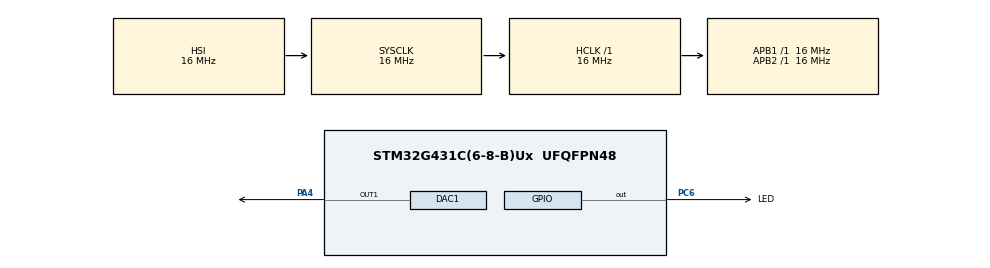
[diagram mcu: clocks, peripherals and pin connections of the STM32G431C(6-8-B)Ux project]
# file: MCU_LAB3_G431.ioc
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Mcu.Family=STM32G4
Mcu.Name=STM32G431C(6-8-B)Ux
Mcu.Package=UFQFPN48
NVIC.PriorityGroup=NVIC_PRIORITYGROUP_4
NVIC.TIM1_BRK_TIM15_IRQn=true\:0\:0\:false\:false\:true\:true\:true\:true
NVIC.TIM1_CC_IRQn=true\:0\:0\:false\:false\:true\:true\:true\:true
NVIC.TIM1_TRG_COM_TIM17_IRQn=true\:0\:0\:false\:false\:true\:true\:true\:true
NVIC.TIM1_UP_TIM16_IRQn=true\:0\:0\:false\:false\:true\:true\:true\:true
PA4.Signal=COMP_DAC11_group
PC6.GPIO_Label=LED
PC6.Signal=GPIO_Output
ProjectManager.HeapSize=0x200
ProjectManager.StackSize=0x400
ProjectManager.TargetToolchain=STM32CubeIDE
RCC.AHBFreq_Value=16000000
RCC.APB1Freq_Value=16000000
RCC.APB1TimFreq_Value=16000000
RCC.APB2Freq_Value=16000000
RCC.APB2TimFreq_Value=16000000
RCC.CortexFreq_Value=16000000
RCC.EXTERNAL_CLOCK_VALUE=12288000
RCC.HCLKFreq_Value=16000000
RCC.HSE_VALUE=8000000
RCC.HSI48_VALUE=48000000
RCC.HSI_VALUE=16000000
RCC.LSE_VALUE=32768
RCC.SYSCLKFreq_VALUE=16000000
RCC.USBFreq_Value=64000000
RCC.VCOOutputFreq_Value=128000000
SH.COMP_DAC11_group.0=DAC1_OUT1,DAC_OUT1
TIM1.PeriodNoDither=10000+1
TIM1.Prescaler=16+1
VP_SYS_VS_DBSignals.Mode=DisableDeadBatterySignals
VP_TIM1_VS_ClockSourceINT.Mode=Internal
board=custom

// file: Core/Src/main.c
/* USER CODE BEGIN Header */
/**
  ******************************************************************************
  * @file           : main.c
  * @brief          : Main program body
  ******************************************************************************
  * @attention
  *
  * Copyright (c) 2024 STMicroelectronics.
  * All rights reserved.
  *
  * This software is licensed under terms that can be found in the LICENSE file
  * in the root directory of this software component.
  * If no LICENSE file comes with this software, it is provided AS-IS.
  *
  ******************************************************************************
  */
/* USER CODE END Header */
#include "main.h"

/* USER CODE BEGIN Includes */
#include <math.h>
#include <stdio.h>
#include <stdbool.h>
#include <string.h>
/* USER CODE END Includes */

DAC_HandleTypeDef hdac1;

TIM_HandleTypeDef htim1;

void SystemClock_Config(void);
static void MX_GPIO_Init(void);
static void MX_DAC1_Init(void);
static void MX_TIM1_Init(void);

/* USER CODE BEGIN 0 */

int num = 0;
uint32_t time = 0;

char rx_buffer[10];
char tx_buffer[50];
bool cmd_executed = false;

float received_numbers[2];
int numbers_received = 0;

uint32_t w = 0;
float omega = 1.0;

uint32_t wave(uint32_t t);

float phi = -3.14 / 2.0;
float ampl = 0.5;

uint32_t wave(uint32_t t) {
	uint32_t ns = 50; // ns = number samples || ns = 10 - bad || ns = 255 - good
	float v_ref = 3.3;
	float freq = 60.0; // in Hz, should be the same as timer clock
	// 1000000/freq . 16 bit, then PSC need incresde to -> another formula we need
	// my method
	TIM1->ARR = (uint32_t) (1000000/freq);
	TIM1->PSC = 16 + 1;

	// stm method
//	TIM1->ARR = (uint32_t) (1000000/(ns*freq));
//	TIM1->PSC = 16 + 1;
//	omega = 2.0 * 3.14 * freq;
	float b = 0.5;
	float res = b + ampl * sinf( (omega * t)/ns + phi);

	return (uint32_t) ((res / v_ref)* 4096);
//	return (uint32_t) (v_ref/2) * ( ampl * sin( (6.28/ns)*t ) + 1 );

//	// 12-битное DAC, максимальное значение - 0xFFF
//	const uint32_t DAC_MaxDigitalValue = 0xFFF;
//
//	// Угол для текущего сэмпла с учётом фазового сдвига
//	float angle = ((2.0f * 3.14159f * t) / ns) + phi;
//
//	// Генерация значения синуса и масштабирование в диапазон от 0 до DAC_MaxDigitalValue
//	float sineValue = (uint32_t) (sinf(angle) + 1.0f);
//
//	// Преобразование в цифровое значение для DAC (с учётом VREF)
//	return (uint32_t) ( 4096 * (sineValue / (3.3/2)) );

}

//void get_sineval ()
//{
//	for (int i=0;i<1000;i++)
//	{
//		sine_val[i] = ((sin(i*2*3.14/100) + 1)*(4096/2));
//
//	}
//}

void HAL_TIM_PeriodElapsedCallback(TIM_HandleTypeDef *htim){
	if (htim == &htim1){
		if(htim->Instance == TIM1){
			time++; // t is discrete
			w = wave(time);
			HAL_DAC_SetValue(&hdac1, DAC_CHANNEL_1, DAC_ALIGN_12B_R, w);

//			uint8_t buff[10];
//			num++;
//			sprintf(buff, "%d", num);

//			HAL_UART_Transmit_IT(&huart2, buff, 10);
			HAL_GPIO_TogglePin(LED_GPIO_Port, LED_Pin);

		}
	}
}

//void HAL_UART_RxCpltCallback(UART_HandleTypeDef *huart) {
////    if (huart->Instance == USART2 {
//
//        float number;
//        if (sscanf(rx_buffer, "%f", &number) == 1) {
//            received_numbers[numbers_received] = number;
//            numbers_received++;
//        }
//
//        if (numbers_received == 2) {
//            snprintf(tx_buffer, sizeof(tx_buffer), "got numbers, plotting a sin\n");
//            HAL_UART_Transmit(&huart2, (uint8_t*)tx_buffer, strlen(tx_buffer), HAL_MAX_DELAY);
//
//            numbers_received = 0;
//        }
//
//        memset(rx_buffer, 0, sizeof(rx_buffer));
//        HAL_UART_Receive_IT(&huart2, (uint8_t*)rx_buffer, sizeof(rx_buffer) - 1);
//}

/* USER CODE END 0 */

int main(void)
{

  /* MCU Configuration--------------------------------------------------------*/

  /* Reset of all peripherals, Initializes the Flash interface and the Systick. */
  HAL_Init();

  /* Configure the system clock */
  SystemClock_Config();

  /* Initialize all configured peripherals */
  MX_GPIO_Init();
  MX_DAC1_Init();
  MX_TIM1_Init();
  /* USER CODE BEGIN 2 */
  HAL_DAC_Start(&hdac1, DAC_CHANNEL_1);
  HAL_TIM_Base_Start_IT(&htim1);
  /* USER CODE END 2 */

  /* Infinite loop */
  while (1)
  {

  }
}

void SystemClock_Config(void)
{
  RCC_OscInitTypeDef RCC_OscInitStruct = {0};
  RCC_ClkInitTypeDef RCC_ClkInitStruct = {0};

  /** Configure the main internal regulator output voltage
  */
  HAL_PWREx_ControlVoltageScaling(PWR_REGULATOR_VOLTAGE_SCALE1);

  /** Initializes the RCC Oscillators according to the specified parameters
  * in the RCC_OscInitTypeDef structure.
  */
  RCC_OscInitStruct.OscillatorType = RCC_OSCILLATORTYPE_HSI;
  RCC_OscInitStruct.HSIState = RCC_HSI_ON;
  RCC_OscInitStruct.HSICalibrationValue = RCC_HSICALIBRATION_DEFAULT;
  RCC_OscInitStruct.PLL.PLLState = RCC_PLL_NONE;
  if (HAL_RCC_OscConfig(&RCC_OscInitStruct) != HAL_OK)
  {
    Error_Handler();
  }

  /** Initializes the CPU, AHB and APB buses clocks
  */
  RCC_ClkInitStruct.ClockType = RCC_CLOCKTYPE_HCLK|RCC_CLOCKTYPE_SYSCLK
                              |RCC_CLOCKTYPE_PCLK1|RCC_CLOCKTYPE_PCLK2;
  RCC_ClkInitStruct.SYSCLKSource = RCC_SYSCLKSOURCE_HSI;
  RCC_ClkInitStruct.AHBCLKDivider = RCC_SYSCLK_DIV1;
  RCC_ClkInitStruct.APB1CLKDivider = RCC_HCLK_DIV1;
  RCC_ClkInitStruct.APB2CLKDivider = RCC_HCLK_DIV1;

  if (HAL_RCC_ClockConfig(&RCC_ClkInitStruct, FLASH_LATENCY_0) != HAL_OK)
  {
    Error_Handler();
  }
}

static void MX_DAC1_Init(void)
{

  DAC_ChannelConfTypeDef sConfig = {0};

  /** DAC Initialization
  */
  hdac1.Instance = DAC1;
  if (HAL_DAC_Init(&hdac1) != HAL_OK)
  {
    Error_Handler();
  }

  /** DAC channel OUT1 config
  */
  sConfig.DAC_HighFrequency = DAC_HIGH_FREQUENCY_INTERFACE_MODE_AUTOMATIC;
  sConfig.DAC_DMADoubleDataMode = DISABLE;
  sConfig.DAC_SignedFormat = DISABLE;
  sConfig.DAC_SampleAndHold = DAC_SAMPLEANDHOLD_DISABLE;
  sConfig.DAC_Trigger = DAC_TRIGGER_NONE;
  sConfig.DAC_Trigger2 = DAC_TRIGGER_NONE;
  sConfig.DAC_OutputBuffer = DAC_OUTPUTBUFFER_ENABLE;
  sConfig.DAC_ConnectOnChipPeripheral = DAC_CHIPCONNECT_EXTERNAL;
  sConfig.DAC_UserTrimming = DAC_TRIMMING_FACTORY;
  if (HAL_DAC_ConfigChannel(&hdac1, &sConfig, DAC_CHANNEL_1) != HAL_OK)
  {
    Error_Handler();
  }

}

static void MX_TIM1_Init(void)
{

  TIM_ClockConfigTypeDef sClockSourceConfig = {0};
  TIM_MasterConfigTypeDef sMasterConfig = {0};

  htim1.Instance = TIM1;
  htim1.Init.Prescaler = 16+1;
  htim1.Init.CounterMode = TIM_COUNTERMODE_UP;
  htim1.Init.Period = 10001;
  htim1.Init.ClockDivision = TIM_CLOCKDIVISION_DIV1;
  htim1.Init.RepetitionCounter = 0;
  htim1.Init.AutoReloadPreload = TIM_AUTORELOAD_PRELOAD_DISABLE;
  if (HAL_TIM_Base_Init(&htim1) != HAL_OK)
  {
    Error_Handler();
  }
  sClockSourceConfig.ClockSource = TIM_CLOCKSOURCE_INTERNAL;
  if (HAL_TIM_ConfigClockSource(&htim1, &sClockSourceConfig) != HAL_OK)
  {
    Error_Handler();
  }
  sMasterConfig.MasterOutputTrigger = TIM_TRGO_RESET;
  sMasterConfig.MasterOutputTrigger2 = TIM_TRGO2_RESET;
  sMasterConfig.MasterSlaveMode = TIM_MASTERSLAVEMODE_DISABLE;
  if (HAL_TIMEx_MasterConfigSynchronization(&htim1, &sMasterConfig) != HAL_OK)
  {
    Error_Handler();
  }

}

static void MX_GPIO_Init(void)
{
  GPIO_InitTypeDef GPIO_InitStruct = {0};

  /* GPIO Ports Clock Enable */
  __HAL_RCC_GPIOA_CLK_ENABLE();
  __HAL_RCC_GPIOC_CLK_ENABLE();

  /*Configure GPIO pin Output Level */
  HAL_GPIO_WritePin(LED_GPIO_Port, LED_Pin, GPIO_PIN_RESET);

  /*Configure GPIO pin : LED_Pin */
  GPIO_InitStruct.Pin = LED_Pin;
  GPIO_InitStruct.Mode = GPIO_MODE_OUTPUT_PP;
  GPIO_InitStruct.Pull = GPIO_NOPULL;
  GPIO_InitStruct.Speed = GPIO_SPEED_FREQ_LOW;
  HAL_GPIO_Init(LED_GPIO_Port, &GPIO_InitStruct);

}

void Error_Handler(void)
{
  __disable_irq();
  while (1)
  {
  }
}
